AUTOSAR XML (schema 00051)
package /S01UCON/Swc
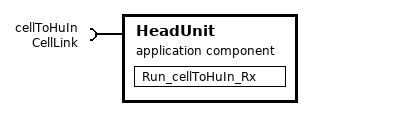
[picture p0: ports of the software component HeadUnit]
  application sw component type HeadUnit  # Application software component type HeadUnit
    require port cellToHuIn: required-interface=CellLink
    behavior Behavior
      data received event Dre_cellToHuIn: start-on-event=Run_cellToHuIn_Rx, data=cellToHuIn.val
      runnable Run_cellToHuIn_Rx
        data-receive-point-by-arguments:
          access Rcv_cellToHuIn: accessed-variable=cellToHuIn.val
  swc implementation HeadUnit_Impl: programming-language=C, sw-version=1.0.0, behavior=HeadUnit/Behavior
  composition sw component type Root  # Composition Root
    4 x component:
      bridge: type=V850Bridge
      ivi: type=HeadUnit
      steer: type=SteeringCtrl
      tel: type=Telematics
    connect tel.cellToHuOut -> ivi.cellToHuIn
  application sw component type SteeringCtrl  # Application software component type SteeringCtrl
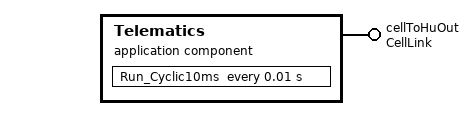
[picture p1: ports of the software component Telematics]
  application sw component type Telematics  # Application software component type Telematics
    provide port cellToHuOut: provided-interface=CellLink
    behavior Behavior
      timing event Tev_Cyclic10ms: start-on-event=Run_Cyclic10ms, period=0.01
      runnable Run_Cyclic10ms
        data-send-points:
          access Snd_cellToHuOut: accessed-variable=cellToHuOut.val
  swc implementation Telematics_Impl: programming-language=C, sw-version=1.0.0, behavior=Telematics/Behavior
  application sw component type V850Bridge  # Application software component type V850Bridge
